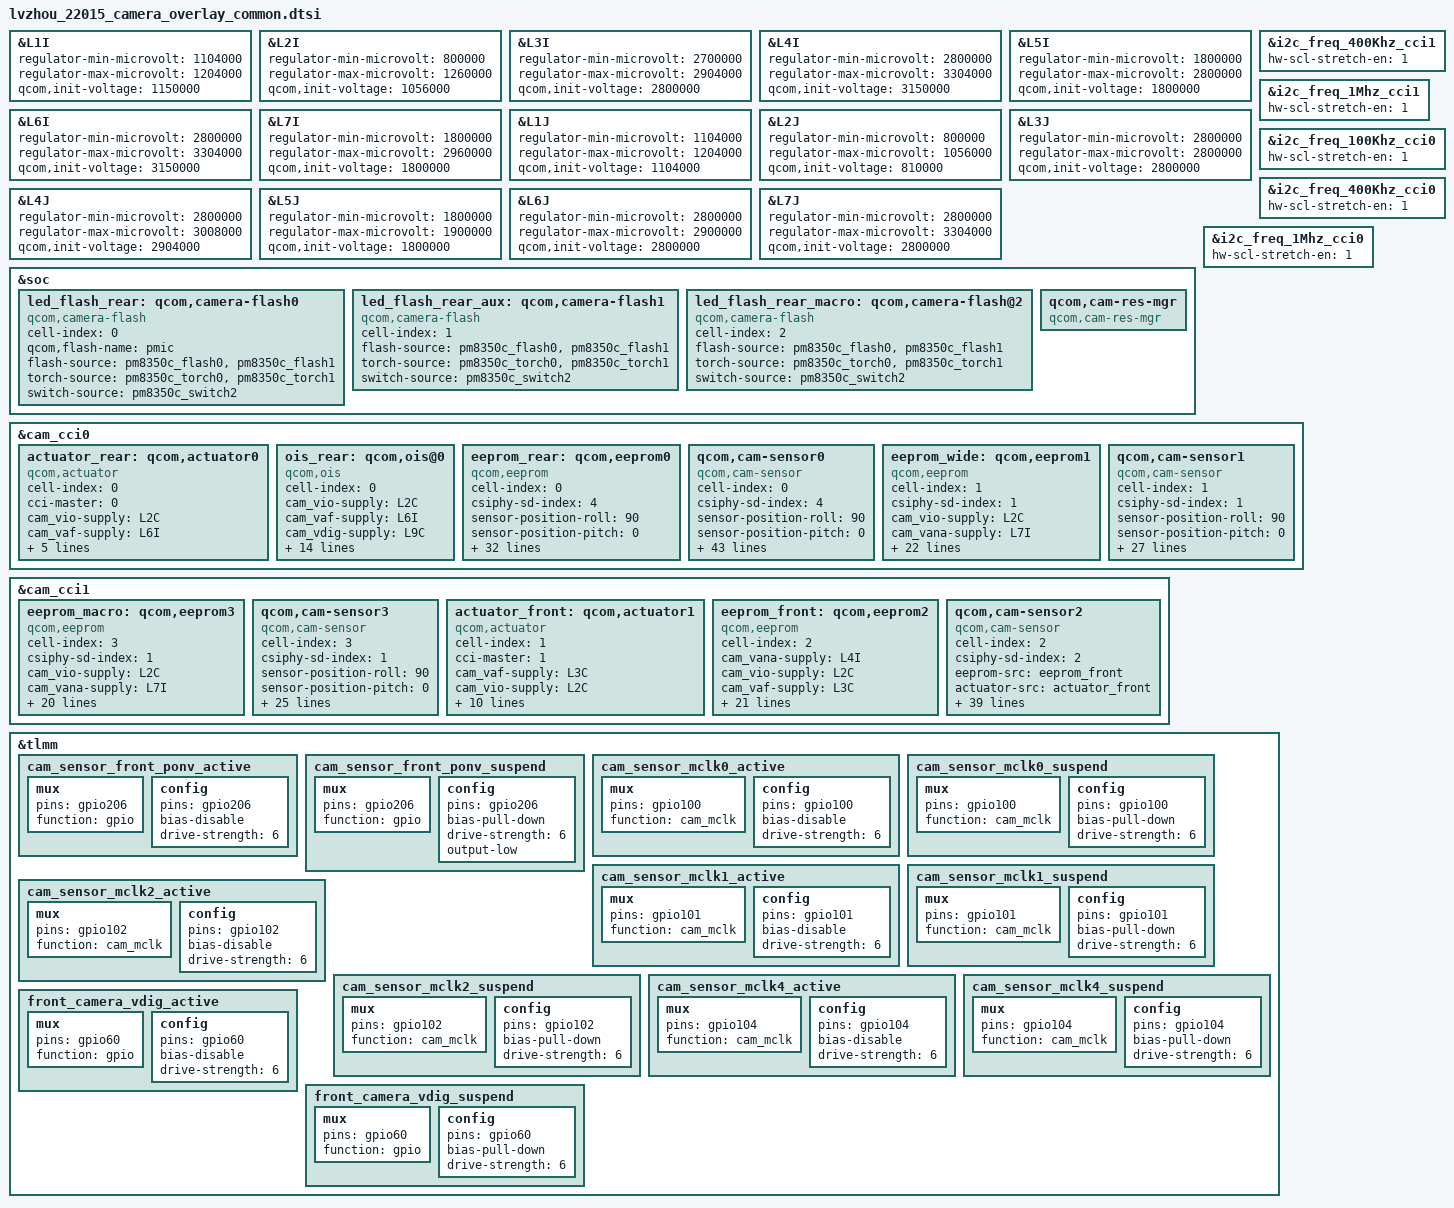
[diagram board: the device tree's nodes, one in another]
#include <dt-bindings/clock/qcom,camcc-waipio.h>

&L1I {
  regulator-min-microvolt = <1104000>;
  regulator-max-microvolt = <1204000>;
  qcom,init-voltage = <1150000>;
};

&L2I {
  regulator-min-microvolt = <800000>;
  regulator-max-microvolt = <1260000>;
  qcom,init-voltage = <1056000>;
};

&L3I {
  regulator-min-microvolt = <2700000>;
  regulator-max-microvolt = <2904000>;
  qcom,init-voltage = <2800000>;
};

&L4I {
  regulator-min-microvolt = <2800000>;
  regulator-max-microvolt = <3304000>;
  qcom,init-voltage = <3150000>;
};

&L5I {
  regulator-min-microvolt = <1800000>;
  regulator-max-microvolt = <2800000>;
  qcom,init-voltage = <1800000>;
};

&L6I {
  regulator-min-microvolt = <2800000>;
  regulator-max-microvolt = <3304000>;
  qcom,init-voltage = <3150000>;
};

&L7I {
  regulator-min-microvolt = <1800000>;
  regulator-max-microvolt = <2960000>;
  qcom,init-voltage = <1800000>;
};

&L1J {
  regulator-min-microvolt = <1104000>;
  regulator-max-microvolt = <1204000>;
  qcom,init-voltage = <1104000>;
};

&L2J {
  regulator-min-microvolt = <800000>;
  regulator-max-microvolt = <1056000>;
  qcom,init-voltage = <810000>;
};

&L3J {
  regulator-min-microvolt = <2800000>;
  regulator-max-microvolt = <2800000>;
  qcom,init-voltage = <2800000>;
};

&L4J {
  regulator-min-microvolt = <2800000>;
  regulator-max-microvolt = <3008000>;
  qcom,init-voltage = <2904000>;
};

&L5J {
  regulator-min-microvolt = <1800000>;
  regulator-max-microvolt = <1900000>;
  qcom,init-voltage = <1800000>;
};

&L6J {
  regulator-min-microvolt = <2800000>;
  regulator-max-microvolt = <2900000>;
  qcom,init-voltage = <2800000>;
};

&L7J {
  regulator-min-microvolt = <2800000>;
  regulator-max-microvolt = <3304000>;
  qcom,init-voltage = <2800000>;
};

&soc {
	led_flash_rear: qcom,camera-flash0 {
		cell-index = <0>;
		compatible = "qcom,camera-flash";
		qcom,flash-name = "pmic";
		flash-source = <&pm8350c_flash0 &pm8350c_flash1>;
		torch-source = <&pm8350c_torch0 &pm8350c_torch1>;
		switch-source = <&pm8350c_switch2>;
		status = "ok";
	};

	led_flash_rear_aux: qcom,camera-flash1 {
		cell-index = <1>;
		compatible = "qcom,camera-flash";
		flash-source = <&pm8350c_flash0 &pm8350c_flash1>;
		torch-source = <&pm8350c_torch0 &pm8350c_torch1>;
		switch-source = <&pm8350c_switch2>;
		status = "ok";
	};

	led_flash_rear_macro: qcom,camera-flash@2 {
		cell-index = <2>;
		compatible = "qcom,camera-flash";
		flash-source = <&pm8350c_flash0 &pm8350c_flash1>;
		torch-source = <&pm8350c_torch0 &pm8350c_torch1>;
		switch-source = <&pm8350c_switch2>;
		status = "ok";
	};

	qcom,cam-res-mgr {
		compatible = "qcom,cam-res-mgr";
		status = "ok";
	};


};

&i2c_freq_400Khz_cci1 {
    hw-scl-stretch-en = <1>;
};

&i2c_freq_1Mhz_cci1 {
    hw-scl-stretch-en = <1>;
};

&i2c_freq_100Khz_cci0 {
    hw-scl-stretch-en = <1>;
};

&i2c_freq_400Khz_cci0 {
    hw-scl-stretch-en = <1>;
};

&i2c_freq_1Mhz_cci0 {
    hw-scl-stretch-en = <1>;
};

&cam_cci0 {
	actuator_rear: qcom,actuator0 {
		cell-index = <0>;
		compatible = "qcom,actuator";
		cci-master = <0>;
		cam_vio-supply = <&L2C>;
		cam_vaf-supply = <&L6I>;
		regulator-names = "cam_vio", "cam_vaf";
		rgltr-cntrl-support;
		rgltr-min-voltage = <1800000 2852000>;
		rgltr-max-voltage = <1800000 2984000>;
		rgltr-load-current = <300000 300000>;
	};

	ois_rear: qcom,ois@0{
		cell-index = <0>;
		compatible = "qcom,ois";
		cam_vio-supply = <&L2C>;
		cam_vaf-supply = <&L6I>;
		cam_vdig-supply = <&L9C>;
		regulator-names = "cam_vio","cam_vaf","cam_vdig";
		rgltr-cntrl-support;
		rgltr-min-voltage = <1800000 2852000 2852000>;
		rgltr-max-voltage = <1800000 2984000 2984000>;
		rgltr-load-current = <300000 300000 300000>;
		cci-master = <0>;
		ois_gyro,position=<3>;
		ois_gyro,type=<0>;
		ois,type=<0>;
		ois,name="AK7322C";
		ois_module,vendor=<0>;
		ois_actuator,vednor=<7>;
		ois,fw=<1>;
		status = "ok";
		ois_eis_function = <3>;
	};
	eeprom_rear: qcom,eeprom0 {
		cell-index = <0>;
		compatible = "qcom,eeprom";
		csiphy-sd-index = <4>;
		sensor-position-roll = <90>;
		sensor-position-pitch = <0>;
		sensor-position-yaw = <180>;
		cam_vio-supply = <&L2C>;
		cam_vana-supply = <&L3I>;
		cam_v_custom1-supply = <&L5I>;
		cam_vdig-supply = <&L1I>;
		cam_vaf-supply = <&L6I>;
		cam_vana1-supply = <&L9C>;
		cam_clk-supply = <&cam_cc_titan_top_gdsc>;
		regulator-names = "cam_vio", "cam_vana", "cam_v_custom1", "cam_vdig", "cam_vaf","cam_vana1","cam_clk";
		rgltr-cntrl-support;
		rgltr-min-voltage = <1800000 2800000 1800000 1100000 2852000 2852000 0>;
		rgltr-max-voltage = <1800000 2800000 1800000 1204000 2904000 2904000 0>;
		rgltr-load-current = <300000 300000 600000 1200000 300000 300000 0>;
		gpio-no-mux = <0>;
		pinctrl-names = "cam_default", "cam_suspend";
		pinctrl-0 = <&cam_sensor_mclk0_active
			&cam_sensor_active_rst3>;
		pinctrl-1 = <&cam_sensor_mclk0_suspend
			&cam_sensor_suspend_rst3>;
		gpios = <&tlmm 100 0>,
			<&tlmm 120 0>;
		gpio-reset = <1>;
		gpio-req-tbl-num = <0 1>;
		gpio-req-tbl-flags = <1 0>;
		gpio-req-tbl-label = "CAMIF_MCLK0",
					"CAM_RESET3";
		cci-master = <0>;
		clocks = <&clock_camcc CAM_CC_MCLK0_CLK>;
		clock-names = "cam_clk";
		clock-cntl-level = "nominal";
		clock-rates = <19200000>;
		status = "ok";
	};

    //imx766_main
	qcom,cam-sensor0 {//main camera
		cell-index = <0>;
		compatible = "qcom,cam-sensor";
		csiphy-sd-index = <4>;
		sensor-position-roll = <90>;
		sensor-position-pitch = <0>;
		sensor-position-yaw = <180>;
		eeprom-src = <&eeprom_rear>;
		actuator-src = <&actuator_rear>;
		led-flash-src = <&led_flash_rear>;
		ois-src = <&ois_rear>;
		cam_vio-supply = <&L2C>;
		cam_vana-supply = <&L3I>;
		cam_v_custom1-supply = <&L5I>;
		cam_vdig-supply = <&L1I>;
		cam_vaf-supply = <&L6I>;
		cam_vana1-supply = <&L9C>;
		cam_clk-supply = <&cam_cc_titan_top_gdsc>;
		regulator-names = "cam_vio", "cam_vana", "cam_v_custom1", "cam_vdig", "cam_vaf","cam_vana1","cam_clk";
		rgltr-cntrl-support;
		rgltr-min-voltage = <1800000 2800000 1800000 1100000 2852000 2852000 0>;
		rgltr-max-voltage = <1800000 2800000 1800000 1204000 2904000 2904000 0>;
		rgltr-load-current = <300000 300000 600000 1200000 300000 300000 0>;
		gpio-no-mux = <0>;
		pinctrl-names = "cam_default", "cam_suspend";
		pinctrl-0 = <&cam_sensor_mclk0_active
			&cam_sensor_active_rst3>;
		pinctrl-1 = <&cam_sensor_mclk0_suspend
			&cam_sensor_suspend_rst3>;
		gpios = <&tlmm 100 0>,
			<&tlmm 120 0>;
		gpio-reset = <1>;
		gpio-req-tbl-num = <0 1>;
		gpio-req-tbl-flags = <1 0>;
		gpio-req-tbl-label = "CAMIF_MCLK0",
					"CAM_RESET3";
		cci-master = <0>;
		status = "ok";
		clocks = <&clock_camcc CAM_CC_MCLK0_CLK>;
		clock-names = "cam_clk";
		clock-cntl-level = "nominal";
		clock-rates = <19200000>;
		is-read-eeprom = <2>;
		is_power_up_advance = <1>;
		enable_qsc_write_in_advance = <1>;
		qsc_reg_addr = <0x1E30>;
		eeprom_slave_addr = <0xA0>;
		qsc_data_size = <3072>;
		write_qsc_addr = <0xC800>;
	};

	eeprom_wide: qcom,eeprom1 {
		cell-index = <1>;
		compatible = "qcom,eeprom";
		csiphy-sd-index = <1>;
		cam_vio-supply = <&L2C>;
		cam_vana-supply = <&L7I>;
		cam_vdig-supply = <&L2I>;
		cam_clk-supply = <&cam_cc_titan_top_gdsc>;
		regulator-names = "cam_vio", "cam_vana", "cam_vdig",
			"cam_clk";
		rgltr-cntrl-support;
		rgltr-min-voltage = <1800000 2800000 1200000 0>;
		rgltr-max-voltage = <1800000 2800000 1200000 0>;
		rgltr-load-current = <300000 50000 250000 0>;
		gpio-no-mux = <0>;
		pinctrl-names = "cam_default", "cam_suspend";
		pinctrl-0 = <&cam_sensor_mclk1_active
				 &cam_sensor_active_rst1>;
		pinctrl-1 = <&cam_sensor_mclk1_suspend
				 &cam_sensor_suspend_rst1>;
		gpios = <&tlmm 101 0>,
			<&tlmm 24 0>;
		gpio-reset = <1>;
		gpio-req-tbl-num = <0 1>;
		gpio-req-tbl-flags = <1 0>;
		gpio-req-tbl-label = "CAMIF_MCLK1",
					"CAM_RESET1";
		cci-master = <1>;
		clocks = <&clock_camcc CAM_CC_MCLK1_CLK>;
		clock-names = "cam_clk";
		clock-cntl-level = "nominal";
		clock-rates = <19200000>;
		status = "ok";
	};

	//ov08d_wide
	qcom,cam-sensor1 {
		cell-index = <1>;
		compatible = "qcom,cam-sensor";
		csiphy-sd-index = <1>;
		sensor-position-roll = <90>;
		sensor-position-pitch = <0>;
		sensor-position-yaw = <180>;
		eeprom-src = <&eeprom_wide>;
		//actuator-src = <&actuator_triple_uw>;
		led-flash-src = <&led_flash_rear_aux>;
		cam_vio-supply = <&L2C>;
		cam_vana-supply = <&L7I>;
		cam_vdig-supply = <&L2I>;
		cam_clk-supply = <&cam_cc_titan_top_gdsc>;
		regulator-names = "cam_vio", "cam_vana", "cam_vdig",
			"cam_clk";
		rgltr-cntrl-support;
		rgltr-min-voltage = <1800000 2800000 1200000 0>;
		rgltr-max-voltage = <1800000 2800000 1200000 0>;
		rgltr-load-current = <300000  50000 250000 0>;
		gpio-no-mux = <0>;
		pinctrl-names = "cam_default", "cam_suspend";
		pinctrl-0 = <&cam_sensor_mclk1_active
				 &cam_sensor_active_rst1>;
		pinctrl-1 = <&cam_sensor_mclk1_suspend
				 &cam_sensor_suspend_rst1>;
		gpios = <&tlmm 101 0>,
			<&tlmm 24 0>;
		gpio-reset = <1>;
		gpio-req-tbl-num = <0 1>;
		gpio-req-tbl-flags = <1 0>;
		gpio-req-tbl-label = "CAMIF_MCLK1",
					"CAM_RESET1";
		cci-master = <1>;
		clocks = <&clock_camcc CAM_CC_MCLK1_CLK>;
		clock-names = "cam_clk";
		clock-cntl-level = "nominal";
		clock-rates = <19200000>;
		status = "ok";
	};
};

&cam_cci1 {
	eeprom_macro: qcom,eeprom3 {
		cell-index = <3>;
		compatible = "qcom,eeprom";
		csiphy-sd-index = <1>;
		cam_vio-supply = <&L2C>;
		cam_vana-supply = <&L7I>;
		//cam_vdig-supply = <&L2I>;
		cam_clk-supply = <&cam_cc_titan_top_gdsc>;
		regulator-names = "cam_vio", "cam_vana",
			"cam_clk";
		rgltr-cntrl-support;
		rgltr-min-voltage = <1800000 2800000 0>;
		rgltr-max-voltage = <1800000 2800000 0>;
		rgltr-load-current = <120000 80000 0>;
		gpio-no-mux = <0>;
		pinctrl-names = "cam_default", "cam_suspend";
		pinctrl-0 = <&cam_sensor_mclk2_active
				 &cam_sensor_active_rst0>;
		pinctrl-1 = <&cam_sensor_mclk2_suspend
				 &cam_sensor_suspend_rst0>;
		gpios = <&tlmm 102 0>,
			<&tlmm 25 0>;
		gpio-reset = <1>;
		gpio-req-tbl-num = <0 1>;
		gpio-req-tbl-flags = <1 0>;
		gpio-req-tbl-label = "CAMIF_MCLK2",
					"CAM_RESET0";
		cci-master = <0>;
		clocks = <&clock_camcc CAM_CC_MCLK2_CLK>;
		clock-names = "cam_clk";
		clock-cntl-level = "nominal";
		clock-rates = <19200000>;
		status = "ok";
	};

    //ov02d10_macro
	qcom,cam-sensor3 {
		cell-index = <3>;
		compatible = "qcom,cam-sensor";
		csiphy-sd-index = <1>;
		sensor-position-roll = <90>;
		sensor-position-pitch = <0>;
		sensor-position-yaw = <180>;
		eeprom-src = <&eeprom_macro>;
		led-flash-src = <&led_flash_rear_macro>;
		cam_vio-supply = <&L2C>;
		cam_vana-supply = <&L7I>;
		cam_clk-supply = <&cam_cc_titan_top_gdsc>;
		regulator-names = "cam_vio", "cam_vana",
			"cam_clk";
		rgltr-cntrl-support;
		rgltr-min-voltage = <1800000 2800000 0>;
		rgltr-max-voltage = <1800000 2800000 0>;
		rgltr-load-current = <120000 80000 0>;
		gpio-no-mux = <0>;
		pinctrl-names = "cam_default", "cam_suspend";
		pinctrl-0 = <&cam_sensor_mclk2_active
				 &cam_sensor_active_rst0>;
		pinctrl-1 = <&cam_sensor_mclk2_suspend
				 &cam_sensor_suspend_rst0>;
		gpios = <&tlmm 102 0>,
			<&tlmm 25 0>;
		gpio-reset = <1>;
		gpio-req-tbl-num = <0 1>;
		gpio-req-tbl-flags = <1 0>;
		gpio-req-tbl-label = "CAMIF_MCLK2",
					"CAM_RESET0";
		cci-master = <0>;
		clocks = <&clock_camcc CAM_CC_MCLK2_CLK>;
		clock-names = "cam_clk";
		clock-cntl-level = "nominal";
		clock-rates = <19200000>;
		status = "ok";
	};

	actuator_front: qcom,actuator1 {
		cell-index = <1>;
		compatible = "qcom,actuator";
		cci-master = <1>;
		cam_vaf-supply = <&L3C>;
		cam_vio-supply = <&L2C>;
		regulator-names = "cam_vaf","cam_vio";
		rgltr-cntrl-support;
		rgltr-min-voltage = <2800000 1800000>;
		rgltr-max-voltage = <2800000 1800000>;
		rgltr-load-current = <300000 300000>;
		is_aon_af = <1>;
		aon_af_slave = <24>;
		aon_eeprom_slave = <168>;
		actuator,name = "dw9718p";
                is_af_parklens = <1>;
	};

	eeprom_front: qcom,eeprom2 {
		cell-index = <2>;
		compatible = "qcom,eeprom";
		cam_vana-supply = <&L4I>;
		cam_vio-supply = <&L2C>;
		cam_vaf-supply = <&L3C>;
		cam_clk-supply = <&cam_cc_titan_top_gdsc>;
		regulator-names ="cam_vana","cam_vio", "cam_vaf", "cam_clk";
		rgltr-cntrl-support;
		rgltr-min-voltage = <2900000 1800000 2800000 0>;
		rgltr-max-voltage = <2900000 1800000 2800000 0>;
		rgltr-load-current = <300000 300000 300000 0>;
		gpio-no-mux = <0>;
		pinctrl-names = "cam_default", "cam_suspend";
		pinctrl-0 = <&cam_sensor_mclk4_active
			&cam_sensor_active_rst6>;
		pinctrl-1 = <&cam_sensor_mclk4_suspend
			&cam_sensor_suspend_rst6>;
		gpios = <&tlmm 104 0>,
			<&tlmm 108 0>;
		gpio-reset = <1>;
		gpio-req-tbl-num = <0 1>;
		gpio-req-tbl-flags = <1 0>;
		gpio-req-tbl-label = "CAMIF_MCLK4",
					"CAM_RESET6";
		cci-master = <1>;
		clocks = <&clock_camcc CAM_CC_MCLK4_CLK>;
		clock-names = "cam_clk";
		clock-cntl-level = "nominal";
		clock-rates = <19200000>;
		status = "ok";
	};

    //imx709_front
	qcom,cam-sensor2 {//front camera
		cell-index = <2>;
		compatible = "qcom,cam-sensor","zeku,aon-sensor";
		csiphy-sd-index = <2>;
		eeprom-src = <&eeprom_front>;
		actuator-src = <&actuator_front>;
		sensor-position-roll = <270>;
		sensor-position-pitch = <0>;
		sensor-position-yaw = <180>;
		cam_vana-supply = <&L4I>;
		cam_vio-supply = <&L2C>;
		cam_vaf-supply = <&L3C>;
		cam_vdig-supply = <&S12B>;
		cam_clk-supply = <&cam_cc_titan_top_gdsc>;
		regulator-names ="cam_vana","cam_vio", "cam_vaf","cam_vdig", "cam_clk";
		rgltr-cntrl-support;
		rgltr-min-voltage = <2900000 1800000 2800000 1250000 0>;
		rgltr-max-voltage = <2900000 1800000 2800000 1400000 0>;
		rgltr-load-current = <300000 300000 300000 300000 0>;
		gpio-no-mux = <0>;
		pinctrl-names = "cam_default", "cam_suspend";
		pinctrl-0 = <&cam_sensor_mclk4_active
			&cam_sensor_active_rst6
			&front_camera_vdig_active
			&cam_sensor_front_ponv_active>;
		pinctrl-1 = <&cam_sensor_mclk4_suspend
			&cam_sensor_suspend_rst6
			&front_camera_vdig_suspend
			&cam_sensor_front_ponv_suspend>;
		gpios = <&tlmm 104 0>,
			<&tlmm 108 0>,
			<&tlmm 60 0>,
			<&tlmm 206 0>;
		gpio-reset = <1>;
		gpio-vdig = <2>;
		gpio-custom1 = <3>;
		gpio-req-tbl-num = <0 1 2 3>;
		gpio-req-tbl-flags = <1 0 0 0>;
		gpio-req-tbl-label = "CAMIF_MCLK4",
					"CAM_RESET6",
					"CAM_FRONT_DVDD",
					"CAM_PONV_FRONT";
		cci-master = <1>;
		qcom-aon-irq-gpio = <&tlmm 85 0>;
		clocks = <&clock_camcc CAM_CC_MCLK4_CLK>;
		clock-names = "cam_clk";
		clock-cntl-level = "nominal";
		clock-rates = <19200000>;
		status = "ok";
	};
};

&tlmm {
	cam_sensor_front_ponv_active: cam_sensor_front_ponv_active {
		/* RESET */
		mux {
			pins = "gpio206";
			function = "gpio";
		};

		config {
			pins = "gpio206";
			bias-disable; /* No PULL */
			drive-strength = <6>; /* 2 MA */
		};
	};

	cam_sensor_front_ponv_suspend: cam_sensor_front_ponv_suspend {
		/* RESET */
		mux {
			pins = "gpio206";
			function = "gpio";
		};

		config {
			pins = "gpio206";
			bias-pull-down; /* PULL DOWN */
			drive-strength = <6>; /* 2 MA */
			output-low;
		};
	};

	cam_sensor_mclk0_active: cam_sensor_mclk0_active {
		/* MCLK0 */
		mux {
			pins = "gpio100";
			function = "cam_mclk";
		};

		config {
			pins = "gpio100";
			bias-disable; /* No PULL */
			drive-strength = <6>; /* 2 MA */
		};
	};

	cam_sensor_mclk0_suspend: cam_sensor_mclk0_suspend {
		/* MCLK0 */
		mux {
			pins = "gpio100";
			function = "cam_mclk";
		};

		config {
			pins = "gpio100";
			bias-pull-down; /* PULL DOWN */
			drive-strength = <6>; /* 2 MA */
		};
	};

	cam_sensor_mclk1_active: cam_sensor_mclk1_active {
		/* MCLK1 */
		mux {
			pins = "gpio101";
			function = "cam_mclk";
		};

		config {
			pins = "gpio101";
			bias-disable; /* No PULL */
			drive-strength = <6>; /* 2 MA */
		};
	};

	cam_sensor_mclk1_suspend: cam_sensor_mclk1_suspend {
		/* MCLK1 */
		mux {
			pins = "gpio101";
			function = "cam_mclk";
		};

		config {
			pins = "gpio101";
			bias-pull-down; /* PULL DOWN */
			drive-strength = <6>; /* 2 MA */
		};
	};

	cam_sensor_mclk2_active: cam_sensor_mclk2_active {
		/* MCLK2 */
		mux {
			pins = "gpio102";
			function = "cam_mclk";
		};

		config {
			pins = "gpio102";
			bias-disable; /* No PULL */
			drive-strength = <6>; /* 2 MA */
		};
	};

	cam_sensor_mclk2_suspend: cam_sensor_mclk2_suspend {
		/* MCLK2 */
		mux {
			pins = "gpio102";
			function = "cam_mclk";
		};

		config {
			pins = "gpio102";
			bias-pull-down; /* PULL DOWN */
			drive-strength = <6>; /* 2 MA */
		};
	};

	cam_sensor_mclk4_active: cam_sensor_mclk4_active {
		/* MCLK4 */
		mux {
			pins = "gpio104";
			function = "cam_mclk";
		};

		config {
			pins = "gpio104";
			bias-disable; /* No PULL */
			drive-strength = <6>; /* 2 MA */
		};
	};

	cam_sensor_mclk4_suspend: cam_sensor_mclk4_suspend {
		/* MCLK4 */
		mux {
			pins = "gpio104";
			function = "cam_mclk";
		};

		config {
			pins = "gpio104";
			bias-pull-down; /* PULL DOWN */
			drive-strength = <6>; /* 2 MA */
		};
	};

	front_camera_vdig_active:front_camera_vdig_active{
		/*  VDD LDO */
		mux {
			pins = "gpio60";
			function = "gpio";
		};

		config {
			pins = "gpio60";
			bias-disable; /* No PULL */
			drive-strength = <6>; /* 2 MA */
		};
	};

	front_camera_vdig_suspend:front_camera_vdig_suspend{
		/*  VDD LDO */
		mux {
			pins = "gpio60";
			function = "gpio";
		};

		config {
			pins = "gpio60";
			bias-pull-down; /* No PULL */
			drive-strength = <6>; /* 2 MA */
		};
	};
};
